# PIC32MX440F256H register map
Registers are 32-bit, access not given, reset 0x0 unless marked. A register's access mark holds for its fields unless they carry their own. Offsets are from the block's base; [hi:lo] are bit positions; {n}, {i} and the like mark numbered series; 'fields as' and 'values as' point back to an identical list.

## USB — USB peripheral
Base 0xBF885040
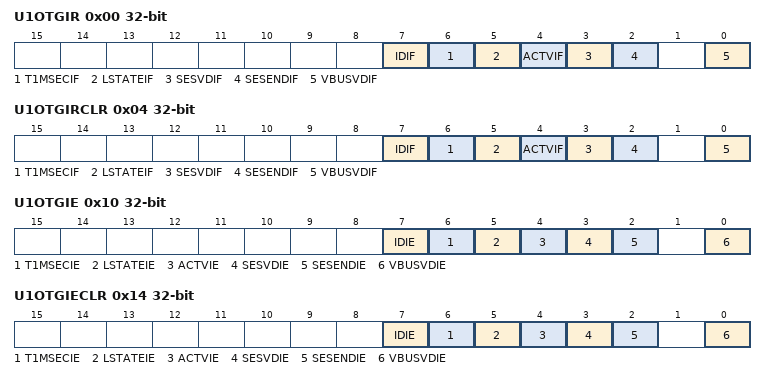
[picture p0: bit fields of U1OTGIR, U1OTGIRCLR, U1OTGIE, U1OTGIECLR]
0x00 U1OTGIR
  [7] IDIF, [6] T1MSECIF, [5] LSTATEIF, [4] ACTVIF, [3] SESVDIF, [2] SESENDIF, [0] VBUSVDIF
0x04 U1OTGIRCLR
  fields as U1OTGIR
0x10 U1OTGIE
  [7] IDIE, [6] T1MSECIE, [5] LSTATEIE, [4] ACTVIE, [3] SESVDIE, [2] SESENDIE, [0] VBUSVDIE
0x14 U1OTGIECLR
  fields as U1OTGIE
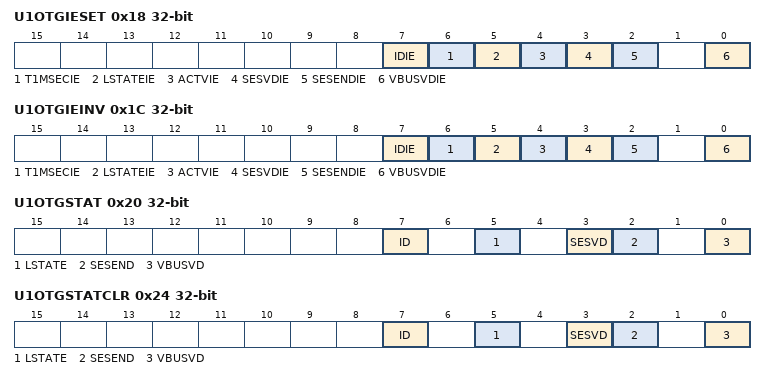
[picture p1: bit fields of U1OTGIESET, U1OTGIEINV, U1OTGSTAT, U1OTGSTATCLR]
0x18 U1OTGIESET
  fields as U1OTGIE
0x1C U1OTGIEINV
  fields as U1OTGIE
0x20 U1OTGSTAT
  [7] ID, [5] LSTATE, [3] SESVD, [2] SESEND, [0] VBUSVD
0x24 U1OTGSTATCLR
  [7] ID, [5] LSTATE, [3] SESVD, [2] SESEND, [0] VBUSVD
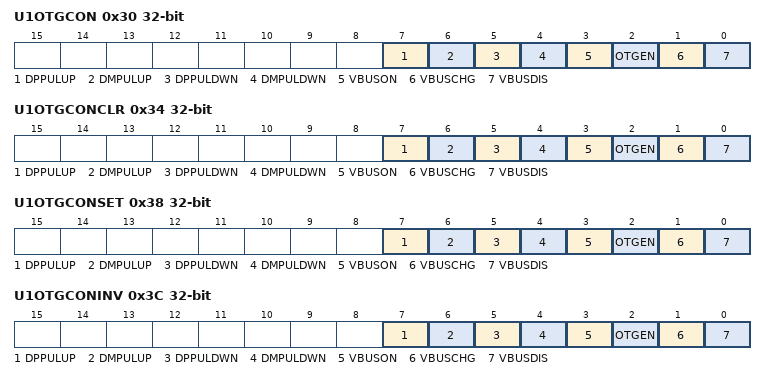
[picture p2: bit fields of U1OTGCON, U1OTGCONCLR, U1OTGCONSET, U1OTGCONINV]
0x30 U1OTGCON
  [7] DPPULUP, [6] DMPULUP, [5] DPPULDWN, [4] DMPULDWN, [3] VBUSON, [2] OTGEN, [1] VBUSCHG, [0] VBUSDIS
0x34 U1OTGCONCLR
  fields as U1OTGCON
0x38 U1OTGCONSET
  fields as U1OTGCON
0x3C U1OTGCONINV
  fields as U1OTGCON
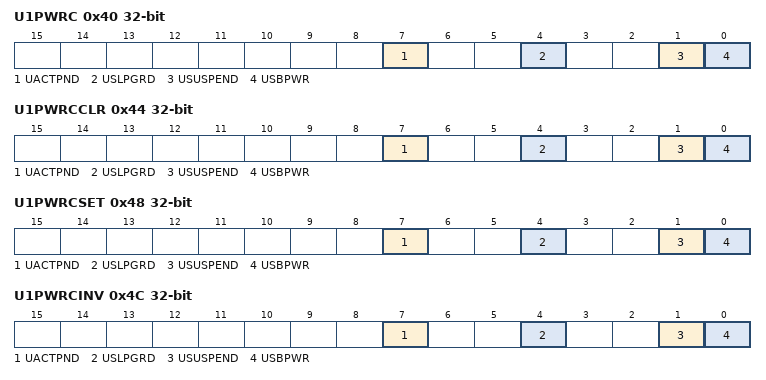
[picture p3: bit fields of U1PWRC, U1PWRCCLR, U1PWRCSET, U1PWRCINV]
0x40 U1PWRC
  [7] UACTPND, [4] USLPGRD, [1] USUSPEND, [0] USBPWR
0x44 U1PWRCCLR
  [7] UACTPND, [4] USLPGRD, [1] USUSPEND, [0] USBPWR
0x48 U1PWRCSET
  [7] UACTPND, [4] USLPGRD, [1] USUSPEND, [0] USBPWR
0x4C U1PWRCINV
  [7] UACTPND, [4] USLPGRD, [1] USUSPEND, [0] USBPWR
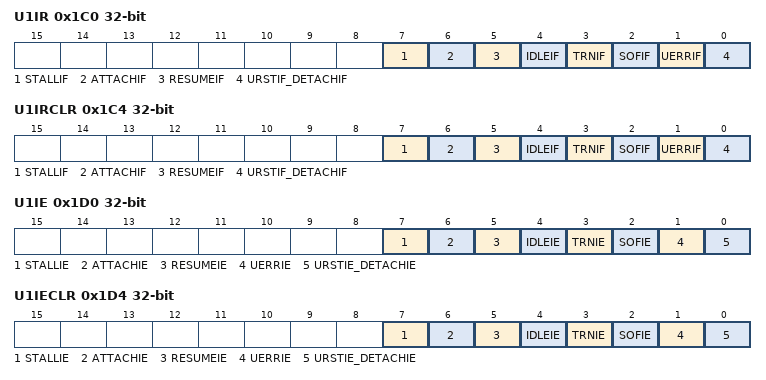
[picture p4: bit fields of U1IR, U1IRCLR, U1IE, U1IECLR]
0x1C0 U1IR
  [7] STALLIF, [6] ATTACHIF, [5] RESUMEIF, [4] IDLEIF, [3] TRNIF, [2] SOFIF, [1] UERRIF, [0] URSTIF_DETACHIF
0x1C4 U1IRCLR
  fields as U1IR
0x1D0 U1IE
  [7] STALLIE, [6] ATTACHIE, [5] RESUMEIE, [4] IDLEIE, [3] TRNIE, [2] SOFIE, [1] UERRIE, [0] URSTIE_DETACHIE
0x1D4 U1IECLR
  fields as U1IE
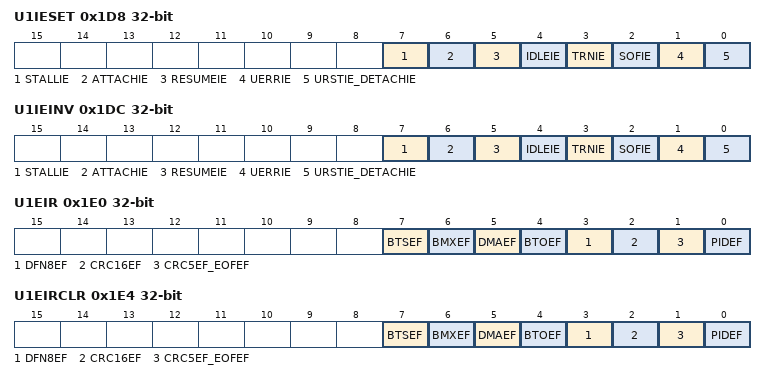
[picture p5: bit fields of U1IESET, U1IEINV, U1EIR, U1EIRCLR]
0x1D8 U1IESET
  fields as U1IE
0x1DC U1IEINV
  fields as U1IE
0x1E0 U1EIR
  [7] BTSEF, [6] BMXEF, [5] DMAEF, [4] BTOEF, [3] DFN8EF, [2] CRC16EF, [1] CRC5EF_EOFEF, [0] PIDEF
0x1E4 U1EIRCLR
  fields as U1EIR
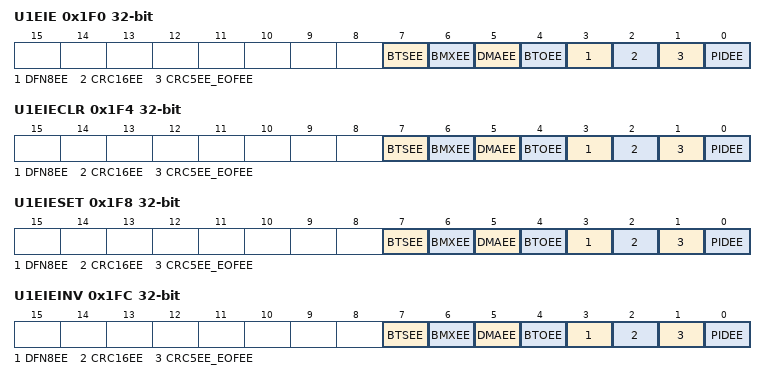
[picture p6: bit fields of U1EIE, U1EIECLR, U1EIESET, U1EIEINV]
0x1F0 U1EIE
  [7] BTSEE, [6] BMXEE, [5] DMAEE, [4] BTOEE, [3] DFN8EE, [2] CRC16EE, [1] CRC5EE_EOFEE, [0] PIDEE
0x1F4 U1EIECLR
  fields as U1EIE
0x1F8 U1EIESET
  fields as U1EIE
0x1FC U1EIEINV
  fields as U1EIE
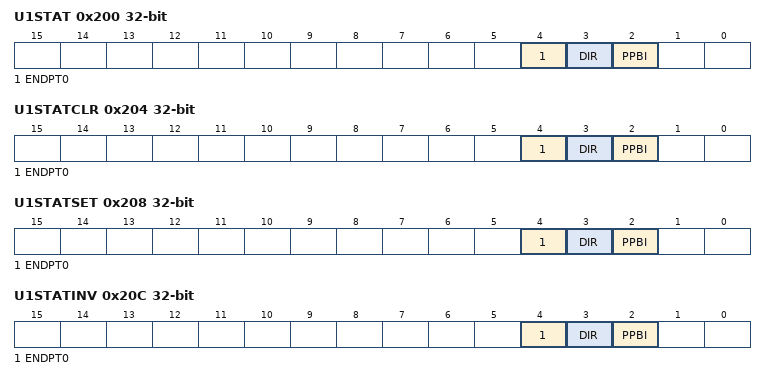
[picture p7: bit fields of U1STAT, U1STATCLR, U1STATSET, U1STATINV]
0x200 U1STAT
  [4] ENDPT0, [3] DIR, [2] PPBI
0x204 U1STATCLR
  [4] ENDPT0, [3] DIR, [2] PPBI
0x208 U1STATSET
  [4] ENDPT0, [3] DIR, [2] PPBI
0x20C U1STATINV
  [4] ENDPT0, [3] DIR, [2] PPBI
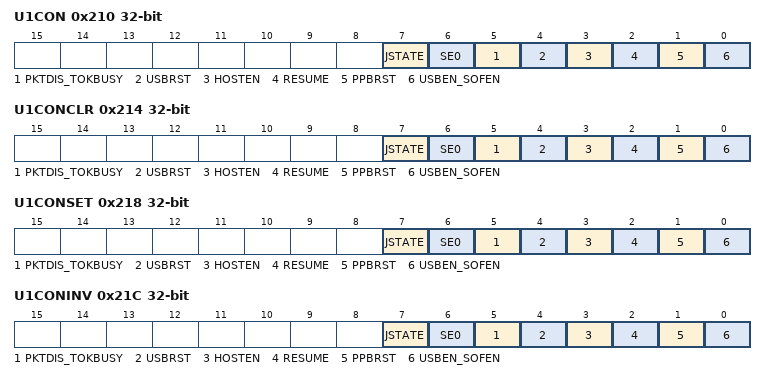
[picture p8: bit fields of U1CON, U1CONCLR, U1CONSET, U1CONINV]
0x210 U1CON
  [7] JSTATE, [6] SE0, [5] PKTDIS_TOKBUSY, [4] USBRST, [3] HOSTEN, [2] RESUME, [1] PPBRST, [0] USBEN_SOFEN
0x214 U1CONCLR
  fields as U1CON
0x218 U1CONSET
  fields as U1CON
0x21C U1CONINV
  fields as U1CON
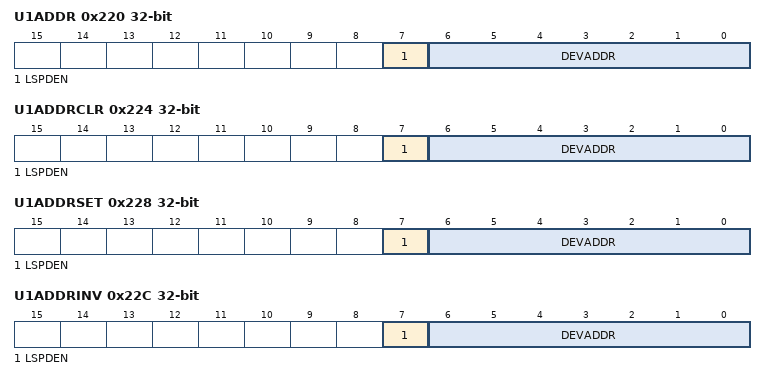
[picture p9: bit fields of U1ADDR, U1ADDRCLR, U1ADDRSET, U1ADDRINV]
0x220 U1ADDR
  [7] LSPDEN, [6:0] DEVADDR
0x224 U1ADDRCLR
  [7] LSPDEN, [6:0] DEVADDR
0x228 U1ADDRSET
  [7] LSPDEN, [6:0] DEVADDR
0x22C U1ADDRINV
  [7] LSPDEN, [6:0] DEVADDR
0x230 U1BDTP1
  [7:1] BDTPTRL
0x234 U1BDTP1CLR
  [7:1] BDTPTRL
0x238 U1BDTP1SET
  [7:1] BDTPTRL
0x23C U1BDTP1INV
  [7:1] BDTPTRL
0x240 U1FRML
  [7:0] FRML
0x244 U1FRMLCLR
  [7:0] FRML
0x248 U1FRMLSET
  [7:0] FRML
0x24C U1FRMLINV
  [7:0] FRML
0x250 U1FRMH
  [2:0] FRMH
0x254 U1FRMHCLR
  [2:0] FRMH
0x258 U1FRMHSET
  [2:0] FRMH
0x25C U1FRMHINV
  [2:0] FRMH
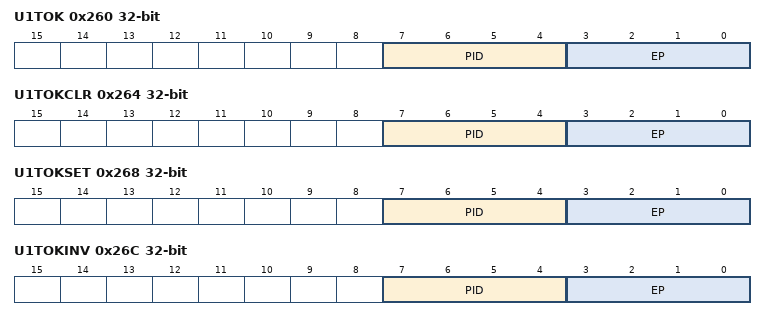
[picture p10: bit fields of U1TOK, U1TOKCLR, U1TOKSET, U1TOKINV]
0x260 U1TOK
  [7:4] PID, [3:0] EP
0x264 U1TOKCLR
  [7:4] PID, [3:0] EP
0x268 U1TOKSET
  [7:4] PID, [3:0] EP
0x26C U1TOKINV
  [7:4] PID, [3:0] EP
0x270 U1SOF
  [7:0] CNT
0x274 U1SOFCLR
  [7:0] CNT
0x278 U1SOFSET
  [7:0] CNT
0x27C U1SOFINV
  [7:0] CNT
0x280 U1BDTP2
  [7:0] BDTPTRH
0x284 U1BDTP2CLR
  [7:0] BDTPTRH
0x288 U1BDTP2SET
  [7:0] BDTPTRH
0x28C U1BDTP2INV
  [7:0] BDTPTRH
0x290 U1BDTP3
  [7:0] BDTPTRU
0x294 U1BDTP3CLR
  [7:0] BDTPTRU
0x298 U1BDTP3SET
  [7:0] BDTPTRU
0x29C U1BDTP3INV
  [7:0] BDTPTRU
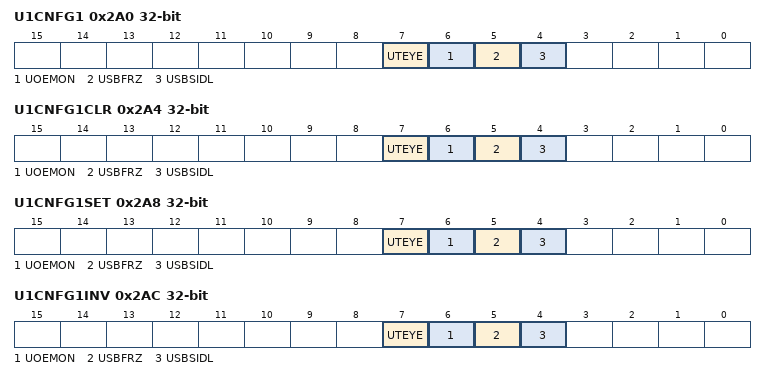
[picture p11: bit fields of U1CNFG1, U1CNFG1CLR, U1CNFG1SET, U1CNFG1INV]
0x2A0 U1CNFG1
  [7] UTEYE, [6] UOEMON, [5] USBFRZ, [4] USBSIDL
0x2A4 U1CNFG1CLR
  [7] UTEYE, [6] UOEMON, [5] USBFRZ, [4] USBSIDL
0x2A8 U1CNFG1SET
  [7] UTEYE, [6] UOEMON, [5] USBFRZ, [4] USBSIDL
0x2AC U1CNFG1INV
  [7] UTEYE, [6] UOEMON, [5] USBFRZ, [4] USBSIDL
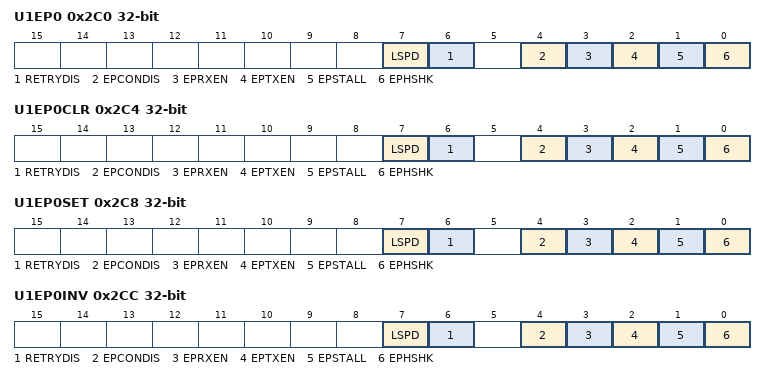
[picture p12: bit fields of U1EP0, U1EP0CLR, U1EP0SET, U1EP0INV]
0x2C0 U1EP0
  [7] LSPD, [6] RETRYDIS, [4] EPCONDIS, [3] EPRXEN, [2] EPTXEN, [1] EPSTALL, [0] EPHSHK
0x2C4 U1EP0CLR
  fields as U1EP0
0x2C8 U1EP0SET
  fields as U1EP0
0x2CC U1EP0INV
  fields as U1EP0
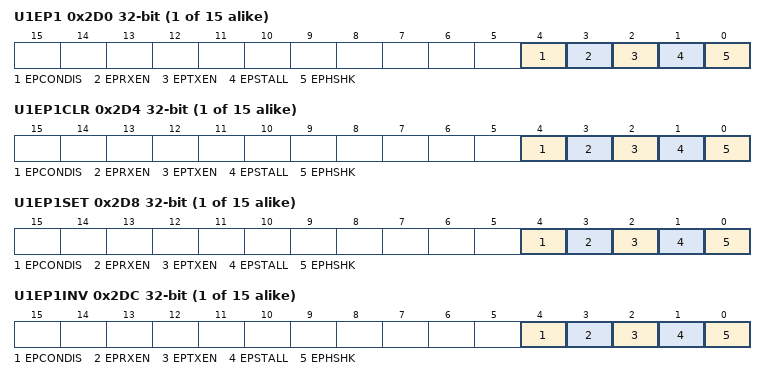
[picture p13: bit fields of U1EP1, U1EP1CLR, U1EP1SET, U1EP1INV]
{0x2C0+0x10*i} U1EP{i} (i=1..15)
  [4] EPCONDIS, [3] EPRXEN, [2] EPTXEN, [1] EPSTALL, [0] EPHSHK
{0x2C4+0x10*i} U1EP{i}CLR (i=1..15)
  [4] EPCONDIS, [3] EPRXEN, [2] EPTXEN, [1] EPSTALL, [0] EPHSHK
{0x2C8+0x10*i} U1EP{i}SET (i=1..15)
  [4] EPCONDIS, [3] EPRXEN, [2] EPTXEN, [1] EPSTALL, [0] EPHSHK
{0x2CC+0x10*i} U1EP{i}INV (i=1..15)
  [4] EPCONDIS, [3] EPRXEN, [2] EPTXEN, [1] EPSTALL, [0] EPHSHK
